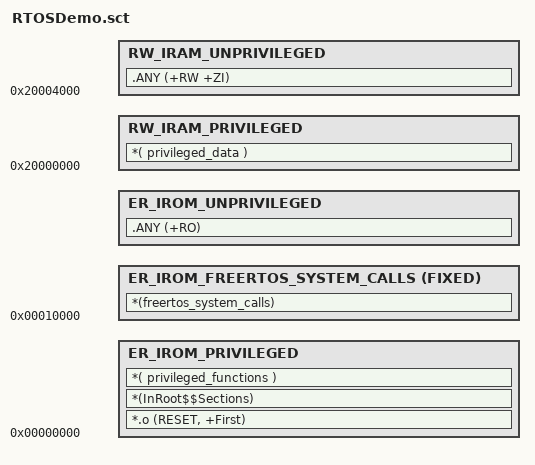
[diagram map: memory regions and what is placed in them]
; *************************************************************
; *** Scatter-Loading Description File generated by uVision ***
; *************************************************************


LR_IROM1 0x00000000  {    ; load region size_region
  ER_IROM_PRIVILEGED 0x00000000  {  ; load address = execution address
   *.o (RESET, +First)
   *(InRoot$$Sections)
   *( privileged_functions )
  }
  ER_IROM_FREERTOS_SYSTEM_CALLS 0x00010000 FIXED {
    *(freertos_system_calls)
  }
  ER_IROM_UNPRIVILEGED +0 {
    .ANY (+RO)
  }
  RW_IRAM_PRIVILEGED 0x20000000  {  ; RW data
   *( privileged_data )
  }
  RW_IRAM_UNPRIVILEGED 0x20004000 {  ; RW data
   .ANY (+RW +ZI)
  }
}


